# STM32U345 register map
File version: 1.0
CPU: CM33 r0p1, little endian, MPU, FPU, 4 interrupt priority bits
Registers are 32-bit, read-write, reset 0x0 unless marked. A register's access mark holds for its fields unless they carry their own. Offsets are from the block's base; [hi:lo] are bit positions; {n}, {i} and the like mark numbered series; 'fields as' and 'values as' point back to an identical list.

## RCC (part 2 of 2) — RCC register block
Base 0x40030C00
Same registers: RCC_S 0x50030C00
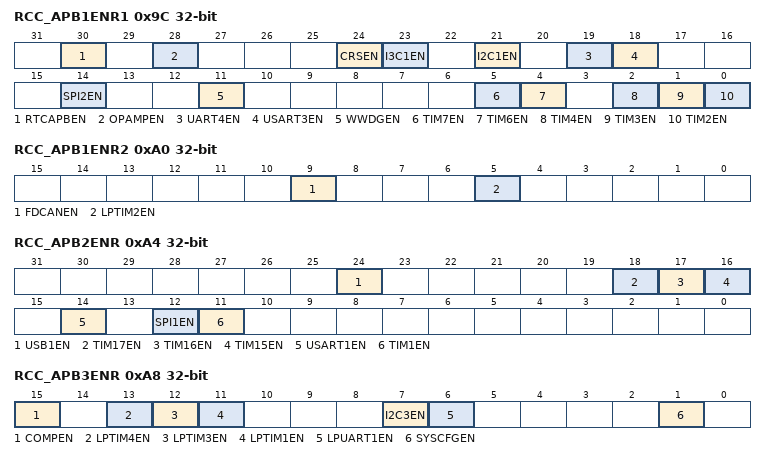
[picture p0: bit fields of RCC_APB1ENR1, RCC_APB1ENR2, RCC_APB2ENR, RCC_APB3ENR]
0x9C RCC_APB1ENR1
  [30] RTCAPBEN — RTC and TAMP APB clock enable
    0=RTC and TAMP APB clock disabled; 1=RTC and TAMP APB clock enabled
  [28] OPAMPEN — OPAMP clock enable
    0=OPAMP clock disabled; 1=OPAMP clock enabled
  [24] CRSEN — CRS clock enable
    0=CRS clock disabled; 1=CRS clock enabled
  [23] I3C1EN — I3C1 clock enable
    0=I3C1 clock disabled; 1=I3C1 clock enabled
  [21] I2C1EN — I2C1 clock enable
    0=I2C1 clock disabled; 1=I2C1 clock enabled
  [19] UART4EN — UART4 clock enable
    0=UART4 clock disabled; 1=UART4 clock enabled
  [18] USART3EN — USART3 clock enable
    0=USART3 clock disabled; 1=USART3 clock enabled
  [14] SPI2EN — SPI2 clock enable
    0=SPI2 clock disabled; 1=SPI2 clock enabled
  [11] WWDGEN — WWDG clock enable Set by software to enable the window watchdog clock. Reset by hardware system reset. This bit can also be set by hardware if the WWDG_SW option bit is reset.
    0=WWDG clock disabled; 1=WWDG clock enabled
  [5] TIM7EN — TIMj clock enable
    0=TIMj clock disabled; 1=TIMj clock enabled
  [4] TIM6EN — TIMj clock enable
    0=TIMj clock disabled; 1=TIMj clock enabled
  [2] TIM4EN — TIMj clock enable
    0=TIMj clock disabled; 1=TIMj clock enabled
  [1] TIM3EN — TIMj clock enable
    0=TIMj clock disabled; 1=TIMj clock enabled
  [0] TIM2EN — TIMj clock enable
    0=TIMj clock disabled; 1=TIMj clock enabled
0xA0 RCC_APB1ENR2
  [9] FDCANEN — FDCAN1 and FDCAN2 clock enable Note: FDCAN2 is only available on STM32U3B5/3C5.
    0=FDCAN1 and FDCAN2 clock disabled; 1=FDCAN1 and FDCAN2 clock enabled
  [5] LPTIM2EN — LPTIM2 clock enable
    0=LPTIM2 clock disabled; 1=LPTIM2 clock enabled
0xA4 RCC_APB2ENR
  [24] USB1EN — USB1 clock enable
    0=USB1 clock disabled; 1=USB1 clock enabled
  [18] TIM17EN — TIMi clock enable
    0=TIMi clock disabled; 1=TIMi clock enabled
  [17] TIM16EN — TIMi clock enable
    0=TIMi clock disabled; 1=TIMi clock enabled
  [16] TIM15EN — TIMi clock enable
    0=TIMi clock disabled; 1=TIMi clock enabled
  [14] USART1EN — USART1clock enable
    0=USART1 clock disabled; 1=USART1 clock enabled
  [12] SPI1EN — SPI1 clock enable
    0=SPI1 clock disabled; 1=SPI1 clock enabled
  [11] TIM1EN — TIM1 clock enable
    0=TIM1 clock disabled; 1=TIM1 clock enabled
0xA8 RCC_APB3ENR
  [15] COMPEN — COMP clock enable
    0=COMP clock disabled; 1=COMP clock enabled
  [13] LPTIM4EN — LPTIMi clock enable
    0=LPTIMi clock disabled; 1=LPTIMi clock enabled
  [12] LPTIM3EN — LPTIMi clock enable
    0=LPTIMi clock disabled; 1=LPTIMi clock enabled
  [11] LPTIM1EN — LPTIM1 clock enable
    0=LPTIM1 clock disabled; 1=LPTIM1 clock enabled
  [7] I2C3EN — I2C3 clock enable
    0=I2C3 clock disabled; 1=I2C3 clock enabled
  [6] LPUART1EN — LPUART1 clock enable
    0=LPUART1 clock disabled; 1=LPUART1 clock enabled
  [1] SYSCFGEN — SYSCFG clock enable
    0=SYSCFG clock disabled; 1=SYSCFG clock enabled
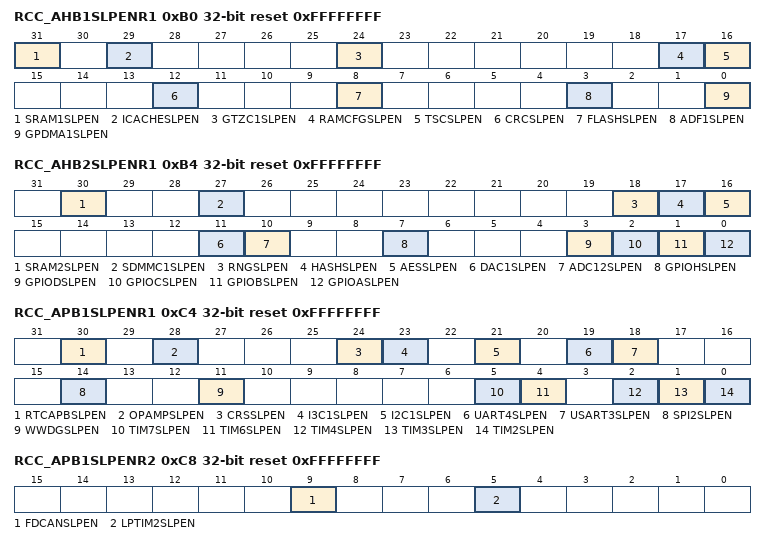
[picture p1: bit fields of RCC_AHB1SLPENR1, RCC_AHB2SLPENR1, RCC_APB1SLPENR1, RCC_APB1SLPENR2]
0xB0 RCC_AHB1SLPENR1 reset 0xFFFFFFFF — This register only configures the clock gating, not the clock source itself. When a bit is set in Stop mode, the corresponding peripheral clock is enabled only when a peripheral (this one or another) requests AHB or APB clock (refer to Peripherals clock gating and autonomous mode).
  [31] SRAM1SLPEN — SRAM1 clock enable during Sleep mode
    0=SRAM1 clock disabled by the clock gating during Sleep mode; 1=SRAM1 clock enabled by the clock gating during Sleep mode
  [29] ICACHESLPEN — ICACHE clock enable during Sleep mode
    0=ICACHE clock disabled by the clock gating during Sleep mode; 1=ICACHE clock enabled by the clock gating during Sleep mode
  [24] GTZC1SLPEN — GTZC1 clock enable during Sleep mode
    0=GTZC1 clock disabled by the clock gating during Sleep mode; 1=GTZC1 clock enabled by the clock gating during Sleep mode
  [17] RAMCFGSLPEN — RAMCFG clock enable during Sleep mode
    0=RAMCFG clock disabled by the clock gating during Sleep mode; 1=RAMCFG clock enabled by the clock gating during Sleep mode
  [16] TSCSLPEN — TSC clock enable during Sleep mode
    0=TSC clock disabled by the clock gating during Sleep mode; 1=TSC clock enabled by the clock gating during Sleep mode
  [12] CRCSLPEN — CRC clock enable during Sleep mode
    0=CRC clock disabled by the clock gating during Sleep mode; 1=CRC clock enabled by the clock gating during Sleep mode
  [8] FLASHSLPEN — FLASH clock enable during Sleep mode
    0=FLASH clock disabled by the clock gating during Sleep mode; 1=FLASH clock enabled by the clock gating during Sleep mode
  [3] ADF1SLPEN — ADF1 clock enable during Sleep mode.
    0=ADF1 clock disabled by the clock gating during Sleep mode; 1=ADF1 clock enabled by the clock gating during Sleep mode
  [0] GPDMA1SLPEN — GPDMA1 clock enable during Sleep mode
    0=GPDMA1 clock disabled by the clock gating during Sleep mode; 1=GPDMA1 clock enabled by the clock gating during Sleep mode
0xB4 RCC_AHB2SLPENR1 reset 0xFFFFFFFF — This register only configures the clock gating, not the clock source itself. When a bit is set in Stop mode, the corresponding peripheral clock is enabled only when a peripheral (this one or another) requests AHB or APB clock (refer to Peripherals clock gating and autonomous mode).
  [30] SRAM2SLPEN — SRAM2 clock enable during Sleep mode
    0=SRAM2 clock disabled by the clock gating during Sleep mode; 1=SRAM2 clock enabled by the clock gating during Sleep mode
  [27] SDMMC1SLPEN — SDMMC1 clock enable during Sleep mode
    0=SDMMC1 clock disabled by the clock gating during Sleep mode; 1=SDMMC1 clock enabled by the clock gating during Sleep mode
  [18] RNGSLPEN — RNG clock enable during Sleep mode
    0=RNG clock disabled by the clock gating during Sleep mode; 1=RNG clock enabled by the clock gating during Sleep mode
  [17] HASHSLPEN — HASH clock enable during Sleep mode
    0=HASH clock disabled by the clock gating during Sleep mode; 1=HASH clock enabled by the clock gating during Sleep mode
  [16] AESSLPEN — AES clock enable during Sleep mode
    0=AES clock disabled by the clock gating during Sleep mode; 1=AES clock enabled by the clock gating during Sleep mode
  [11] DAC1SLPEN — DAC1 clock enable during Sleep mode
    0=DAC1 clock disabled by the clock gating during Sleep mode; 1=DAC1 clock enabled by the clock gating during Sleep mode
  [10] ADC12SLPEN — ADC12 clock enable during Sleep mode
    0=ADC12 clock disabled by the clock gating during Sleep mode; 1=ADC12 clock enabled by the clock gating during Sleep mode
  [7] GPIOHSLPEN — I/O port i clock enable during Sleep mode (i = A to H) Note: Port F is only available on STM32U3B5/3C5.
    0=I/O port i clock disabled by the clock gating during Sleep mode; 1=I/O port i clock enabled by the clock gating during Sleep mode
  [3] GPIODSLPEN — I/O port i clock enable during Sleep mode (i = A to H) Note: Port F is only available on STM32U3B5/3C5.
    values as GPIOHSLPEN
  [2] GPIOCSLPEN — I/O port i clock enable during Sleep mode (i = A to H) Note: Port F is only available on STM32U3B5/3C5.
    values as GPIOHSLPEN
  [1] GPIOBSLPEN — I/O port i clock enable during Sleep mode (i = A to H) Note: Port F is only available on STM32U3B5/3C5.
    values as GPIOHSLPEN
  [0] GPIOASLPEN — I/O port i clock enable during Sleep mode (i = A to H) Note: Port F is only available on STM32U3B5/3C5.
    values as GPIOHSLPEN
0xB8 RCC_AHB2SLPENR2 reset 0xFFFFFFFF — This register only configures the clock gating, not the clock source itself. When a bit is set in Stop mode, the corresponding peripheral clock is enabled only when a peripheral (this one or another) requests AHB or APB clock (refer to Peripherals clock gating and autonomous mode).
  [4] OCTOSPI1SLPEN — OCTOSPI1 clock enable during Sleep mode
    0=OCTOSPI1 clock disabled by the clock gating during Sleep mode; 1=OCTOSPI1 clock enabled by the clock gating during Sleep mode
0xBC RCC_AHB1SLPENR2 reset 0xFFFFFFFF — This register only configures the clock gating, not the clock source itself. When a bit is set in Stop mode, the corresponding peripheral clock is enabled only when a peripheral (this one or another) requests AHB or APB clock (refer to Peripherals clock gating and autonomous mode).
  [2] PWRSLPEN — PWR clock enable during Sleep mode
    0=PWR clock disabled by the clock gating during Sleep mode; 1=PWR clock enabled by the clock gating during Sleep mode
0xC4 RCC_APB1SLPENR1 reset 0xFFFFFFFF — This register only configures the clock gating, not the clock source itself. When a bit is set in Stop mode, the corresponding peripheral clock is enabled only when a peripheral (this one or another) requests AHB or APB clock (refer to Peripherals clock gating and autonomous mode).
  [30] RTCAPBSLPEN — RTC and TAMP APB clock enable during Sleep mode
    0=RTC and TAMP APB clock disabled by the clock gating during Sleep mode; 1=RTC and TAMP APB clock enabled by the clock gating during Sleep mode
  [28] OPAMPSLPEN — OPAMP clock enable during Sleep mode
    0=OPAMP clock disabled by the clock gating during Sleep mode; 1=OPAMP clock enabled by the clock gating during Sleep mode
  [24] CRSSLPEN — CRS clock enable during Sleep mode
    0=CRS clock disabled by the clock gating during Sleep mode; 1=CRS clock enabled by the clock gating during Sleep mode
  [23] I3C1SLPEN — I3C1 clock enable during Sleep mode
    0=I3C1 clock disabled by the clock gating during Sleep mode; 1=I3C1 clock enabled by the clock gating during Sleep mode
  [21] I2C1SLPEN — I2C1 clock enable during Sleep mode
    0=I2C1 clock disabled by the clock gating during Sleep mode; 1=I2C1 clock enabled by the clock gating during Sleep mode
  [19] UART4SLPEN — UART4 clock enable during Sleep mode
    0=UART4 clock disabled by the clock gating during Sleep mode; 1=UART4 clock enabled by the clock gating during Sleep mode
  [18] USART3SLPEN — USART3 clock enable during Sleep mode
    0=USART3 clock disabled by the clock gating during Sleep mode; 1=USART3 clock enabled by the clock gating during Sleep mode
  [14] SPI2SLPEN — SPI2 clock enable during Sleep mode
    0=SPI2 clock disabled by the clock gating during Sleep mode; 1=SPI2 clock enabled by the clock gating during Sleep mode
  [11] WWDGSLPEN — WWDG clock enable during Sleep mode This bit is forced to 1 by hardware when the hardware WWDG option is activated.
    0=WWDG clock disabled by the clock gating during Sleep mode; 1=WWDG clock enabled by the clock gating during Sleep mode
  [5] TIM7SLPEN — TIMj clock enable during Sleep mode
    0=TIMj clock disabled by the clock gating during Sleep mode; 1=TIMj clock enabled by the clock gating during Sleep mode
  [4] TIM6SLPEN — TIMj clock enable during Sleep mode
    values as TIM7SLPEN
  [2] TIM4SLPEN — TIMj clock enable during Sleep mode
    values as TIM7SLPEN
  [1] TIM3SLPEN — TIMj clock enable during Sleep mode
    values as TIM7SLPEN
  [0] TIM2SLPEN — TIMj clock enable during Sleep mode
    values as TIM7SLPEN
0xC8 RCC_APB1SLPENR2 reset 0xFFFFFFFF — This register only configures the clock gating, not the clock source itself. When a bit is set in Stop mode, the corresponding peripheral clock is enabled only when a peripheral (this one or another) requests AHB or APB clock (refer to Peripherals clock gating and autonomous mode).
  [9] FDCANSLPEN — FDCAN clock enable during Sleep mode Note: This bit is only available on STM32U3B5/3C5.
    0=FDCAN1 and FDCAN2 clock disabled by the clock gating during Sleep mode; 1=FDCAN1 and FDCAN2 clock enabled by the clock gating during Sleep mode
  [5] LPTIM2SLPEN — LPTIM2 clock enable during Sleep mode
    0=LPTIM2 clock disabled by the clock gating during Sleep mode; 1=LPTIM2 clock enabled by the clock gating during Sleep mode
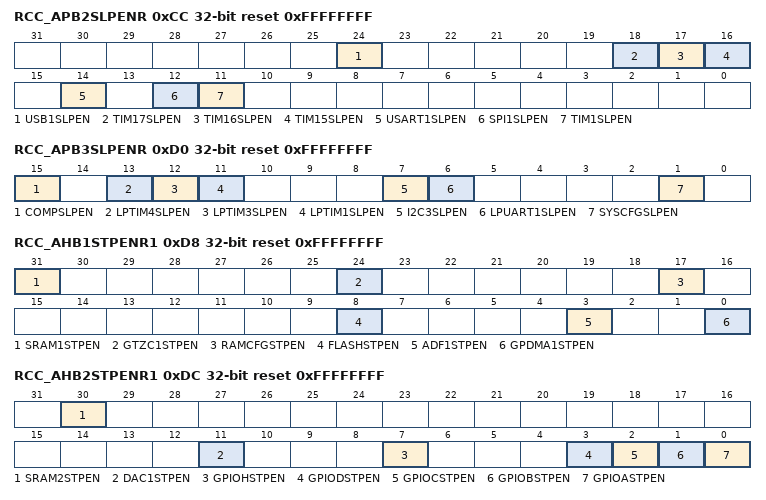
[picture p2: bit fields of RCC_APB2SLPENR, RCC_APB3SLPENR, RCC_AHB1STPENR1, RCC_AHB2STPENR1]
0xCC RCC_APB2SLPENR reset 0xFFFFFFFF — This register only configures the clock gating, not the clock source itself. When a bit is set in Stop mode, the corresponding peripheral clock is enabled only when a peripheral (this one or another) requests AHB or APB clock (refer to Peripherals clock gating and autonomous mode).
  [24] USB1SLPEN — USB1 clock enable during Sleep mode
    0=USB1 clock disabled by the clock gating during Sleep mode; 1=USB1 clock enabled by the clock gating during Sleep mode
  [18] TIM17SLPEN — TIMi clock enable during Sleep mode
    0=TIMi clock disabled during Sleep mode; 1=TIMi clock enabled during Sleep mode
  [17] TIM16SLPEN — TIMi clock enable during Sleep mode
    values as TIM17SLPEN
  [16] TIM15SLPEN — TIMi clock enable during Sleep mode
    values as TIM17SLPEN
  [14] USART1SLPEN — USART1clock enable during Sleep mode
    0=USART1clock disabled by the clock gating during Sleep mode; 1=USART1clock enabled by the clock gating during Sleep mode
  [12] SPI1SLPEN — SPI1 clock enable during Sleep mode
    0=SPI1 clock disabled by the clock gating during Sleep mode; 1=SPI1 clock enabled by the clock gating during Sleep mode
  [11] TIM1SLPEN — TIM1 clock enable during Sleep mode
    0=TIM1 clock disabled during Sleep mode; 1=TIM1 clock enabled during Sleep mode
0xD0 RCC_APB3SLPENR reset 0xFFFFFFFF — This register only configures the clock gating, not the clock source itself. When a bit is set in Stop mode, the corresponding peripheral clock is enabled only when a peripheral (this one or another) requests AHB or APB clock (refer to Peripherals clock gating and autonomous mode).
  [15] COMPSLPEN — COMP clock enable during Sleep mode
    0=COMP clock disabled by the clock gating during Sleep mode; 1=COMP clock enabled by the clock gating during Sleep mode
  [13] LPTIM4SLPEN — LPTIMi clock enable during Sleep mode
    0=LPTIMi clock disabled during Sleep mode; 1=LPTIMi clock enabled during Sleep mode
  [12] LPTIM3SLPEN — LPTIMi clock enable during Sleep mode
    values as LPTIM4SLPEN
  [11] LPTIM1SLPEN — LPTIM1clock enable during Sleep mode
    0=LPTIM1 clock disabled during Sleep mode; 1=LPTIM1 clock enabled during Sleep mode
  [7] I2C3SLPEN — I2C3 clock enable during Sleep mode
    0=I2C3 clock disabled by the clock gating during Sleep mode; 1=I2C3 clock enabled by the clock gating during Sleep mode
  [6] LPUART1SLPEN — LPUART1 clock enable during Sleep mode
    0=LPUART1 clock disabled by the clock gating during Sleep mode; 1=LPUART1 clock enabled by the clock gating during Sleep m
  [1] SYSCFGSLPEN — SYSCFG clock enable during Sleep mode
    0=SYSCFG clock disabled by the clock gating during Sleep mode; 1=SYSCFG clock enabled by the clock gating during Sleep mode
0xD8 RCC_AHB1STPENR1 reset 0xFFFFFFFF — This register only configures the clock gating, not the clock source itself. When a bit is set in Stop mode, the corresponding peripheral clock is enabled only when a peripheral (this one or another) requests AHB or APB clock (refer to Peripherals clock gating and autonomous mode).
  [31] SRAM1STPEN — SRAM1 clock enable during Stop mode
    0=SRAM1 clock disabled by the clock gating during Stop mode; 1=SRAM1 clock enabled by the clock gating during Stop mode
  [24] GTZC1STPEN — GTZC1 clock enable during Stop mode
    0=GTZC1 clock disabled by the clock gating during Stop mode; 1=GTZC1 clock enabled by the clock gating during Stop mode
  [17] RAMCFGSTPEN — RAMCFG clock enable during Stop mode
    0=RAMCFG clock disabled by the clock gating during Stop mode; 1=RAMCFG clock enabled by the clock gating during Stop mode
  [8] FLASHSTPEN — FLASH clock enable during Stop mode
    0=FLASH clock disabled by the clock gating during Stop mode; 1=FLASH clock enabled by the clock gating during Stop mode
  [3] ADF1STPEN — ADF1 clock enable during Stop mode.
    0=ADF1 clock disabled by the clock gating during Stop mode; 1=ADF1 clock enabled by the clock gating during Stop mode
  [0] GPDMA1STPEN — GPDMA1 clock enable during Stop mode.
    0=GPDMA1 clock disabled by the clock gating during Stop mode; 1=GPDMA1 clock enabled by the clock gating during Stop mode
0xDC RCC_AHB2STPENR1 reset 0xFFFFFFFF — This register only configures the clock gating, not the clock source itself. When a bit is set in Stop mode, the corresponding peripheral clock is enabled only when a peripheral (this one or another) requests AHB or APB clock (refer to Peripherals clock gating and autonomous mode).
  [30] SRAM2STPEN — SRAM2 clock enable during Stop mode
    0=SRAM2 clock disabled by the clock gating during Stop mode; 1=SRAM2 clock enabled by the clock gating during Stop mode
  [11] DAC1STPEN — DAC1 clock enable during Stop mode
    0=DAC1 clock disabled by the clock gating during Stop mode; 1=DAC1 clock enabled by the clock gating during Stop mode
  [7] GPIOHSTPEN — I/O port i clock enable during Stop mode (i = H to A) Note: Port F is only available on STM32U3B5/3C5.
    0=I/O port i clock disabled by the clock gating during Stop mode; 1=I/O port i clock enabled by the clock gating during Stop mode
  [3] GPIODSTPEN — I/O port i clock enable during Stop mode (i = H to A) Note: Port F is only available on STM32U3B5/3C5.
    values as GPIOHSTPEN
  [2] GPIOCSTPEN — I/O port i clock enable during Stop mode (i = H to A) Note: Port F is only available on STM32U3B5/3C5.
    values as GPIOHSTPEN
  [1] GPIOBSTPEN — I/O port i clock enable during Stop mode (i = H to A) Note: Port F is only available on STM32U3B5/3C5.
    values as GPIOHSTPEN
  [0] GPIOASTPEN — I/O port i clock enable during Stop mode (i = H to A) Note: Port F is only available on STM32U3B5/3C5.
    values as GPIOHSTPEN
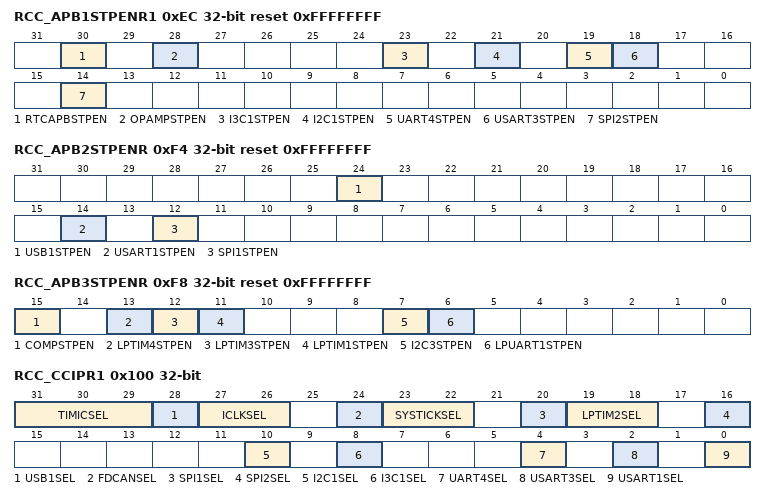
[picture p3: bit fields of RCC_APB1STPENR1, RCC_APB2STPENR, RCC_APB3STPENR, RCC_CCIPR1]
0xEC RCC_APB1STPENR1 reset 0xFFFFFFFF — This register only configures the clock gating, not the clock source itself. When a bit is set in Stop mode, the corresponding peripheral clock is enabled only when a peripheral (this one or another) requests AHB or APB clock (refer to Peripherals clock gating and autonomous mode).
  [30] RTCAPBSTPEN — RTC and TAMP APB clock enable during Stop mode
    0=RTC and TAMP APB clock disabled by the clock gating during Stop mode; 1=RTC and TAMP APB clock enabled by the clock gating during Stop mode
  [28] OPAMPSTPEN — OPAMP clock enable during Stop mode
    0=OPAMP clock disabled by the clock gating during Stop mode; 1=OPAMP clock enabled by the clock gating during Stop mode
  [23] I3C1STPEN — I3C1 clock enable during Stop mode
    0=I3C1 clock disabled by the clock gating during Stop mode; 1=I3C1 clock enabled by the clock gating during Stop mode
  [21] I2C1STPEN — I2C1 clock enable during Stop mode
    0=I2C1 clock disabled by the clock gating during Stop mode; 1=I2C1 clock enabled by the clock gating during Stop mode
  [19] UART4STPEN — UART4 clock enable during Stop mode
    0=UART4 clock disabled by the clock gating during Stop mode; 1=UART4 clock enabled by the clock gating during Stop mode
  [18] USART3STPEN — USART3 clock enable during Stop mode
    0=USART3 clock disabled by the clock gating during Stop mode; 1=USART3 clock enabled by the clock gating during Stop mode
  [14] SPI2STPEN — SPI2 clock enable during Stop mode
    0=SPI2 clock disabled by the clock gating during Stop mode; 1=SPI2 clock enabled by the clock gating during Stop mode
0xF0 RCC_APB1STPENR2 reset 0xFFFFFFFF — This register only configures the clock gating, not the clock source itself. When a bit is set in Stop mode, the corresponding peripheral clock is enabled only when a peripheral (this one or another) requests AHB or APB clock (refer to Peripherals clock gating and autonomous mode).
  [5] LPTIM2STPEN — LPTIM2 clock enable during Stop mode
    0=LPTIM2 clock disabled by the clock gating during Stop mode; 1=LPTIM2 clock enabled by the clock gating during Stop mode
0xF4 RCC_APB2STPENR reset 0xFFFFFFFF — This register only configures the clock gating, not the clock source itself. When a bit is set in Stop mode, the corresponding peripheral clock is enabled only when a peripheral (this one or another) requests AHB or APB clock (refer to Peripherals clock gating and autonomous mode).
  [24] USB1STPEN — USB1 clock enable during Stop mode
    0=USB1 clock disabled by the clock gating during Stop mode; 1=USB1 clock enabled by the clock gating during Stop mode
  [14] USART1STPEN — USART1clock enable during Stop mode
    0=USART1 clock disabled by the clock gating during Stop mode; 1=USART1 clock enabled by the clock gating during Stop mode
  [12] SPI1STPEN — SPI1 clock enable during Stop mode
    0=SPI1 clock disabled by the clock gating during Stop mode; 1=SPI1 clock enabled by the clock gating during Stop mode
0xF8 RCC_APB3STPENR reset 0xFFFFFFFF — This register only configures the clock gating, not the clock source itself. When a bit is set in Stop mode, the corresponding peripheral clock is enabled only when a peripheral (this one or another) requests AHB or APB clock (refer to Peripherals clock gating and autonomous mode).
  [15] COMPSTPEN — COMP clock enable during Stop mode
    0=COMP clock disabled by the clock gating during Stop mode; 1=COMP clock enabled by the clock gating during Stop mode
  [13] LPTIM4STPEN — LPTIMi clock enable during Stop mode
    0=LPTIMi clock disabled during Stop mode; 1=LPTIMi clock enabled during Stop mode
  [12] LPTIM3STPEN — LPTIMi clock enable during Stop mode
    values as LPTIM4STPEN
  [11] LPTIM1STPEN — LPTIM1clock enable during Stop mode
    0=LPTIM1 clock disabled during Stop mode; 1=LPTIM1 clock enabled during Stop mode
  [7] I2C3STPEN — I2C3 clock enable during Stop mode
    0=I2C3 clock disabled by the clock gating during Stop mode; 1=I2C3 clock enabled by the clock gating during Stop mode
  [6] LPUART1STPEN — LPUART1 clock enable during Stop mode
    0=LPUART1 clock disabled by the clock gating during Stop mode; 1=LPUART1 clock enabled by the clock gating during Stop m
0x100 RCC_CCIPR1
  [31:29] TIMICSEL — Clock sources for TIM16,TIM17, and LPTIM2 internal input capture When the TIMICSEL[2] bit is set, TIM16, TIM17, and LPTIM2 internal input capture can be connected either to HSI/256, MSI/4, or MSI/1024. Depending on TIMICSEL[1:0] value, MSI is either MSIK or MSIS. When TIMICSEL[2] is cleared, the HSI, MSIK, and MSIS clock sources cannot be selected as TIM16, TIM17, or LPTIM2 internal input capture. Note: The clock division must be disabled (TIMICSEL[2:0] = 0xx) before selecting or changing a clock source division.
    {v}=HSI, MSIK and MSIS dividers disabled (v=0..3); 4=HSI/256, MSIS/1024 and MSIS/4 are generated and can be selected by TIM16, TIM17, and LPTIM2 as internal input capture; 5=HSI/256, MSIS/1024 and MSIK/4 are generated and can be selected by TIM16, TIM17, and LPTIM2 as internal input capture; 6=HSI/256, MSIK/1024 and MSIS/4 are generated and can be selected by TIM16, TIM17, and LPTIM2 as internal input capture; 7=HSI/256, MSIK/1024 and MSIK/4 are generated and can be selected by TIM16, TIM17, and LPTIM2 as internal input capture
  [28] USB1SEL — USB1 kernel clock prescaler selection This bit is used to configure the division factor of the USB1 kernel clock source selected with ICLKSEL.
    0=usbsdmmc_iclk selected; 1=usbsdmmc_iclk/2 selected
  [27:26] ICLKSEL — Intermediate clock source selection These bits are used to select the clock source for USB and SDMMC (usbsdmmc_iclk).
    0=HSI48 selected; 1=MSIK selected; 2=HSE selected; 3=SYSCLK selected
  [24] FDCANSEL — FDCAN1 and FDCAN2 kernel clock source selection Note: FDCAN2 is only available on STM32U3B5/3C5.
    0=SYSCLK selected; 1=MSIK selected
  [23:22] SYSTICKSEL — SysTick clock source selection Note: When LSE or LSI is selected, the AHB frequency must be at least four times higher than the LSI or LSE frequency. In addition, a jitter up to one HCLK cycle is introduced, due to the LSE or LSI sampling with HCLK in the SysTick circuitry.
    0=HCLK/8 selected; 1=LSI selected; 2=LSE selected
  [20] SPI1SEL — SPI1 kernel clock source selection Note: The SPI1 is functional in Stop 0 or Stop 1 mode only when the kernel clock is MSIK.
    0=PCLK2 selected; 1=MSIK selected
  [19:18] LPTIM2SEL — Low-power timer 2 kernel clock source selection Note: The LPTIM2 is functional in Stop 0 or Stop 1 mode only when the kernel clock is LSI, LSE, or HSI16 if HSIKERON = 1.
    0=PCLK1 selected; 1=LSI selected; 2=HSI16 selected; 3=LSE selected
  [16] SPI2SEL — SPI2 kernel clock source selection Note: The SPI2 is functional in Stop 0 or Stop 1 mode only when the kernel clock is HSI16 or MSIK.
    0=PCLK1 selected; 1=MSIK selected
  [10] I2C1SEL — I2C1 kernel clock source selection Note: The I2C1 is functional in Stop 0 or Stop 1 mode only when the kernel clock is MSIK.
    0=PCLK1 selected; 1=MSIK selected
  [8] I3C1SEL — I3C1 kernel clock source selection Note: The I3C1 is functional in Stop 0 or Stop 1 mode only when the kernel clock is MSIK.
    0=PCLK1 selected; 1=MSIK selected
  [4] UART4SEL — UART4 kernel clock source selection Note: UART4 is functional in Stop 0 or Stop 1 mode only when the kernel clock is HSI16.
    0=PCLK1 selected; 1=HSI16 selected
  [2] USART3SEL — USART3 kernel clock source selection Note: USART3 is functional in Stop 0 or Stop 1 mode only when the kernel clock is HSI16.
    0=PCLK1 selected; 1=HSI16 selected
  [0] USART1SEL — USART1 kernel clock source selection Note: USART1 is functional in Stop 0 or Stop 1 mode only when the kernel clock is HSI16.
    0=PCLK2 selected; 1=HSI16 selected
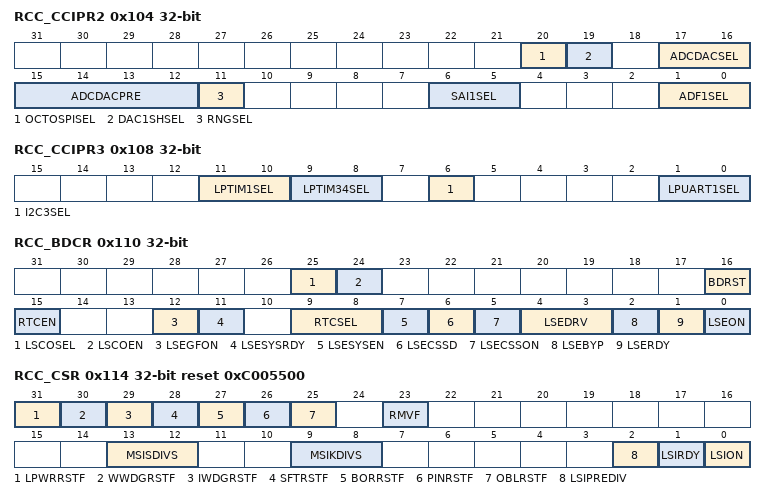
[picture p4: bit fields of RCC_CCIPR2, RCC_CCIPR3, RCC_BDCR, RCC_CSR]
0x104 RCC_CCIPR2
  [20] OCTOSPISEL — OCTOSPI1 kernel clock source selection
    0=SYSCLK selected; 1=MSIK selected
  [19] DAC1SHSEL — DAC1 sample and hold clock source selection
    0=LSE selected; 1=LSI selected
  [17:16] ADCDACSEL — ADC12 and DAC1 intermediate kernel clock source selection These bits are used to select the clock source for the ADC12 and DAC1 (adcdac_iclk)).
    0=HCLK selected; 1=HSE selected; 2=MSIK selected
  [15:12] ADCDACPRE — ADC12 and DAC1 kernel clock prescaler These bits are used to configure the division factor of the ADC12 and DAC1 kernel clock source selected with ADCDACSEL.
    0=adcdac_iclk; {v}=adcdac_iclk/2 (v=1..7); 8=adcdac_iclk/4; 9=adcdac_iclk/8; 10=adcdac_iclk/16; 11=adcdac_iclk/32; 12=adcdac_iclk/64; 13=adcdac_iclk/128; 14=adcdac_iclk/256; 15=adcdac_iclk/512
  [11] RNGSEL — RNG kernel clock source selection
    0=HSI48 selected; 1=MSIK selected
  [6:5] SAI1SEL — SAI1 kernel clock source selection Note: If the selected clock is the external clock and this clock is stopped, a switch to another clock is impossible.
    0=MSIK selected; 1=input pin AUDIOCLK selected; 2=HSE clock selected
  [1:0] ADF1SEL — ADF1 kernel clock source selection Note: f the selected clock is the external clock and this clock is stopped, a switch to another clock is impossible.
    0=HCLK; 1=Input pin AUDIOCLK selected; 2=MSIK clock selected; 3=SAI1 kernel clock selected
0x108 RCC_CCIPR3
  [11:10] LPTIM1SEL — LPTIM1 kernel clock source selection These bits are used to select the LPTIM1 kernel clock source. Note: The LPTIM1 is functional in Stop 0, Stop 1, and Stop 2 modes only when the kernel clock is LSI, LSE, HSI16 with HSIKERON = 1, or MSIK with MSIKERON = 1.
    0=MSIK clock selected; 1=LSI selected; 2=HSI16 selected; 3=LSE selected
  [9:8] LPTIM34SEL — LPTIM3 and LPTIM4 kernel clock source selection Note: LPTIM3 and LPTIM4 are functional in Stop 0, Stop 1, and Stop 2 modes only when the kernel clock is LSI, LSE, HSI16 with HSIKERON = 1, or MSIK with MSIKERON = 1.
    values as LPTIM1SEL
  [6] I2C3SEL — I2C3 kernel clock source selection Note: The I2C3 is functional in Stop 0, Stop 1, and Stop 2 modes only when the kernel clock is MSIK.
    0=PCLK3 selected; 1=MSIK selected
  [1:0] LPUART1SEL — LPUART1 kernel clock source selection Note: The LPUART1 is functional in Stop 0, Stop 1, and Stop 2 modes only when the kernel clock is HSI16, LSE, or MSIK.
    0=PCLK3 selected; 1=HSI16 selected; 2=LSE selected; 3=MSIK selected
0x110 RCC_BDCR reset not defined — Backup domain reset value: 0x0000 X000 Reset by backup domain reset, except LSCOSEL, LSCOEN, and BDRST that are reset only by backup domain power-on reset. LSESYSEN and LSESYSRDY are reset by power-on reset. This register bits are outside of the core domain. As a result, after reset, these bits are write-protected, and DBP in PWR_BDCR must be set before these can be modified (see Section 10.1: RCC introduction). These bits (except LSESYSEN, LSESYSRD, LSCOSEL, LSCOEN, and BDRST) are only reset after a backup domain reset (see Backup domain reset). Any internal or external reset does not have any effect on these bits. Wait states are inserted in case of successive accesses to this register.
  [25] LSCOSEL — Low-speed clock output selection
    0=LSI selected; 1=LSE selected
  [24] LSCOEN — Low-speed clock output (LSCO) enable
    0=LSCO disabled; 1=LSCO enabled
  [16] BDRST — Backup domain software reset
    0=No effect; 1=Reset the entire backup domain
  [15] RTCEN — RTC and TAMP clock enable
    0=RTC and TAMP clock disabled; 1=RTC and TAMP clock enabled
  [12] LSEGFON — LSE clock glitch filter enable This bit can be written only when the LSE is disabled (LSEON = 0 and LSERDY = 0).
    0=LSE glitch filter disabled; 1=LSE glitch filter enabled
  [11] LSESYSRDY — LSE system clock (LSESYS) ready Set and cleared by hardware to indicate when the LSE system clock is stable.When the LSESYSEN bit is set, the LSESYSRDY flag is set after two LSE clock cycles. The LSE clock must be already enabled and stable (LSEON and LSERDY are set). When the LSEON bit is cleared, LSERDY goes low after six external low-speed oscillator clock cycles.
    0=LSESYS clock not ready; 1=LSESYS clock ready
  [9:8] RTCSEL — RTC and TAMP clock source selection Once the RTC and TAMP clock source has been selected, it cannot be changed anymore unless the backup domain is reset, or unless a failure is detected on LSE (LSECSSD is set). The BDRST bit can be used to reset them.
    0=No clock selected; 1=LSE selected; 2=LSI selected; 3=HSE/32 selected
  [7] LSESYSEN — LSE system clock (LSESYS) enable Set by software to enable always the LSE system clock generated by RCC, which can be used by any peripheral when its source clock is the LSE, or at system level if one of LSCO, MCO, or MSI PLL mode is needed.
    0=LSE can be used only for RTC, TAMP, and CSS on LSE; 1=LSE can be used by any other peripheral or function
  [6] LSECSSD — CSS on LSE failure detection Set by hardware to indicate when a failure is detected by the CCS on the external 32 kHz oscillator (LSE). This flag is cleared when LSECSSON = 0.
    0=No failure detected on LSE; 1=Failure detected on LSE
  [5] LSECSSON — CSS on LSE enable This bit must be enabled after the LSE oscillator is enabled (LSEON bit enabled) and ready (LSERDY flag set by hardware), and after the RTCSEL bit is selected. Clearing LSECSSON also clears the LSECSSD bit.
    0=CSS on LSE OFF; 1=CSS on LSE ON
  [4:3] LSEDRV — LSE oscillator drive capability This bit field can be written only when the external 32 kHz oscillator is disabled (LSEON = 0 and LSERDY = 0). Note: The oscillator is in 'Xtal mode' when it is not in bypass mode.
    0='Xtal mode' lower driving capability; 1='Xtal mode' medium-low driving capability; 2='Xtal mode' medium-high driving capability; 3='Xtal mode' higher driving capability
  [2] LSEBYP — LSE oscillator bypass This bit can be written only when the external 32 kHz oscillator is disabled (LSEON = 0 and LSERDY = 0).
    0=LSE oscillator not bypassed; 1=LSE oscillator bypassed
  [1] LSERDY — LSE oscillator ready Set and cleared by hardware to indicate when the external 32 kHz oscillator is stable. After the LSEON bit is cleared, LSERDY goes low after six external low-speed oscillator clock cycles.
    0=LSE oscillator not ready; 1=LSE oscillator ready
  [0] LSEON — LSE oscillator enable
    0=LSE oscillator OFF; 1=LSE oscillator ON
0x114 RCC_CSR reset 0xC005500 — Reset by system reset, except reset flags by power reset only. Wait states are inserted in case of successive accesses to this register.
  [31] LPWRRSTF — Low-power reset flag Set by hardware when a reset occurs due to Stop, Standby, or Shutdown mode entry, whereas the corresponding NRST_STOP, NRST_STBY, or NRST_SHDW option bit is cleared. Cleared by writing to the RMVF bit.
    0=No illegal low-power mode reset occurred; 1=Illegal low-power mode reset occurred
  [30] WWDGRSTF — Window watchdog reset flag Set by hardware when a window watchdog reset occurs. Cleared by writing to the RMVF bit.
    0=No window watchdog reset occurred; 1=Window watchdog reset occurred
  [29] IWDGRSTF — Independent watchdog reset flag Set by hardware when an independent watchdog reset domain occurs. Cleared by writing to the RMVF bit.
    0=No independent watchdog reset occurred; 1=Independent watchdog reset occurred
  [28] SFTRSTF — Software reset flag Set by hardware when a software reset occurs. Cleared by writing to the RMVF bit.
    0=No software reset occurred; 1=Software reset occurred
  [27] BORRSTF — BOR flag Set by hardware when a BOR occurs. Cleared by writing to the RMVF bit.
    0=No BOR occurred; 1=BOR occurred
  [26] PINRSTF — NRST pin reset flag Set by hardware when a reset from the NRST pin occurs. Cleared by writing to the RMVF bit.
    0=No reset from NRST pin occurred; 1=Reset from NRST pin occurred
  [25] OBLRSTF — Option-byte loader reset flag Set by hardware when a reset from the option-byte loading occurs. Cleared by writing to the RMVF bit.
    0=No reset from option-byte loading occurred; 1=Reset from option-byte loading occurred
  [23] RMVF — Remove reset flag
    0=No effect; 1=Clear the reset flags
  [13:12] MSISDIVS — MSIS oscillator division after Standby mode Set by software to choose the MSIS frequency at Standby mode exit, and until MSIRGSEL is set. After a system reset, a power-on reset, or when exiting Shutdown mode, range 5 (12MHz) is always selected. MSISDIVS can be written only when MSIRGSEL = 1. Others: reserved Note: Changing the MSISDIVS does not change the current MSIS frequency.
    1=Range 5 around 12 MHz (reset value); 2=Range 6 around 6 MHz; 3=Range 7 around 3 MHz
  [9:8] MSIKDIVS — MSIK oscillator division after Standby mode Set by software to choose the MSIK frequency at Standby mode exit and until MSIRGSEL is set. After a system reset, a power-on reset or when exiting Shutdown mode, range 5 (12MHz) is always selected. MSIKDIVS can be written only when MSIRGSEL = 1. Others: reserved Note: Changing the MSIKDIVS does not change the current MSIK frequency.
    values as MSISDIVS
  [2] LSIPREDIV — Low-speed clock divider configuration This bit can be written only when the LSI is disabled (LSION = 0 and LSIRDY = 0). If the LSI was previously enabled, it is necessary to wait for LSIRDY = 0 after clearing LSION bit (synchronization time for LSI to be really disabled), before writing LSIPREDIV. LSIPREDIV cannot be changed if the LSI is used by the IWDG, by the RTC, or by the TAMP.
    0=LSI not divided; 1=LSI divided by 128
  [1] LSIRDY — LSI oscillator ready Set and cleared by hardware to indicate when the LSI oscillator is stable. After the LSION bit is cleared, LSIRDY goes low after three internal low-speed oscillator clock cycles. This bit is set when the LSI is used by IWDG, RTC, or TAMP, even if LSION = 0.
    0=LSI oscillator not ready; 1=LSI oscillator ready
  [0] LSION — LSI oscillator enable
    0=LSI oscillator OFF; 1=LSI oscillator ON
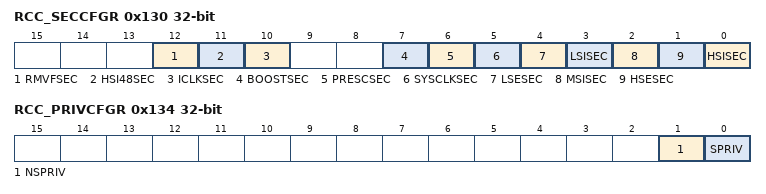
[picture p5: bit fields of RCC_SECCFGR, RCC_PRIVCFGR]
0x130 RCC_SECCFGR — When the system is secure (TZEN = 1), this register can be written only by a secure privileged access if SPRIV = 1, and by a secure privileged or unprivileged access if SPRIV = 0. A nonsecure write access generates an illegal access event and data is not written. This register can be read by secure or nonsecure, privileged or unprivileged access.When the system is not secure (TZEN = 0), this register is read as 0, and the register write is ignored.
  [all] fields
    0=Nonsecure; 1=Secure
  [12] RMVFSEC — Remove reset flag security
  [11] HSI48SEC — HSI48 clock configuration and status bit security
  [10] ICLKSEC — Intermediate clock source selection security
  [7] BOOSTSEC — EPOD booster configuration bit security
  [6] PRESCSEC — AHBx/APBx prescaler configuration bit security
  [5] SYSCLKSEC — SYSCLK clock selection, STOPWUCK bit, clock output on MCO configuration security
  [4] LSESEC — LSE clock configuration and status bit security
  [3] LSISEC — LSI clock configuration and status bit security
  [2] MSISEC — MSI clock configuration and status bit security
  [1] HSESEC — HSE clock configuration, status bits, and HSE_CSS security
  [0] HSISEC — HSI clock configuration and status bit security
0x134 RCC_PRIVCFGR — This register can be written only by a privileged access. It can be read by privileged or unprivileged access.
  [1] NSPRIV — RCC nonsecure function privilege configuration This bit can be written only by privileged access, secure, or nonsecure.
    0=Read and write to RCC nonsecure functions can be done by privileged or unprivileged access; 1=Read and write to RCC nonsecure functions can be done by privileged access only
  [0] SPRIV — RCC secure function privilege configuration This bit can be written only by a secure privileged access.
    0=Read and write to RCC secure functions can be done by privileged or unprivileged access; 1=Read and write to RCC secure functions can be done by privileged access only
